VERSION ""

NS_ :

BS_:

BU_: DAS IRTS_FR STEER DAS TLM IRTS_FR STEER DAS TLM IRTS_FR DAS BMS_LV DAS IRTS_RR BMS_HV IRTS_FR DAS DAS DAS IRTS_RR STEER IRTS_FL DAS TLM DAS IRTS_RR TLM IRTS_FL DAS STEER DAS IRTS_RR STEER IRTS_FL DAS TLM DAS IRTS_RL STEER IRTS_FL DAS TELEMETRY DAS IRTS_RL DAS IMU DAS CONTROL DAS IRTS_RL TELEMETRY IMU DAS DAS IRTS_RL STEER DAS

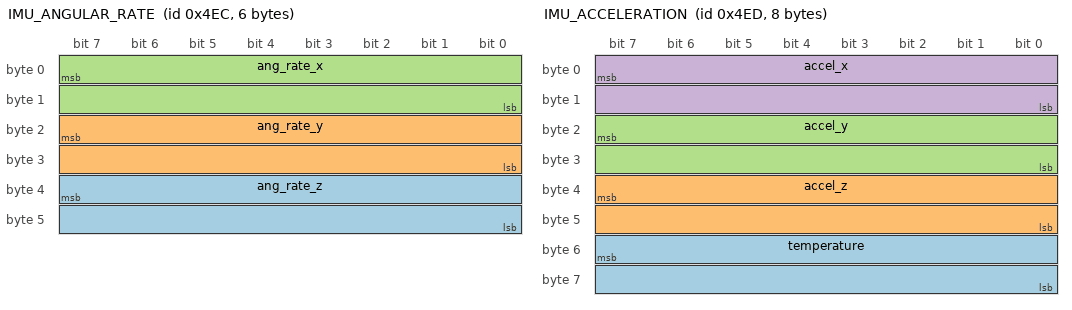
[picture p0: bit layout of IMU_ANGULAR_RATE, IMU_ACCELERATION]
BO_ 1260 IMU_ANGULAR_RATE: 6 Vector__XXX
 SG_ ang_rate_z : 39|16@0- (0.1,0) [0|245] "" Vector__XXX
 SG_ ang_rate_y : 23|16@0- (0.1,0) [0|245] "" Vector__XXX
 SG_ ang_rate_x : 7|16@0- (0.1,0) [0|245] "" Vector__XXX

BO_ 1261 IMU_ACCELERATION: 8 Vector__XXX
 SG_ temperature : 55|16@0- (1,-32768) [-32768|32767] "" Vector__XXX
 SG_ accel_z : 39|16@0- (0.01,0) [0|8] "" Vector__XXX
 SG_ accel_y : 23|16@0- (0.01,0) [0|8] "" Vector__XXX
 SG_ accel_x : 7|16@0- (0.01,0) [0|8] "" Vector__XXX

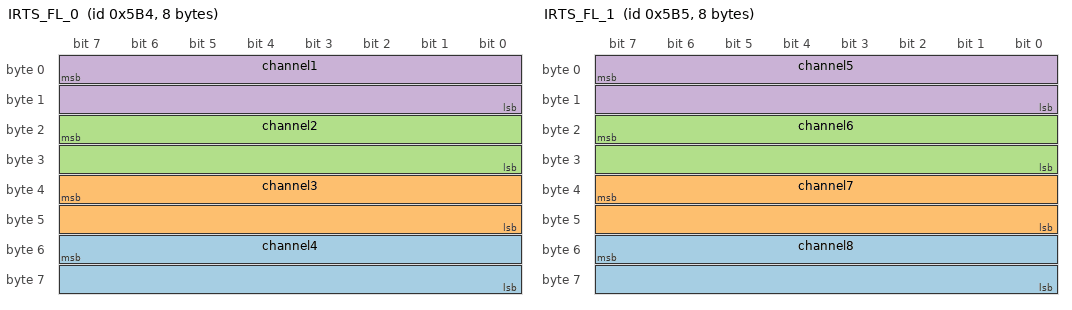
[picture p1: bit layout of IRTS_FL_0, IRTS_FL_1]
BO_ 1460 IRTS_FL_0: 8 Vector__XXX
 SG_ channel4 : 55|16@0+ (0.09775171065493646,-100) [-100|0] "" Vector__XXX
 SG_ channel3 : 39|16@0+ (0.09775171065493646,-100) [-100|0] "" Vector__XXX
 SG_ channel2 : 23|16@0+ (0.09775171065493646,-100) [-100|0] "" Vector__XXX
 SG_ channel1 : 7|16@0+ (0.09775171065493646,-100) [-100|0] "" Vector__XXX

BO_ 1461 IRTS_FL_1: 8 Vector__XXX
 SG_ channel8 : 55|16@0+ (0.09775171065493646,-100) [-100|0] "" Vector__XXX
 SG_ channel7 : 39|16@0+ (0.09775171065493646,-100) [-100|0] "" Vector__XXX
 SG_ channel6 : 23|16@0+ (0.09775171065493646,-100) [-100|0] "" Vector__XXX
 SG_ channel5 : 7|16@0+ (0.09775171065493646,-100) [-100|0] "" Vector__XXX

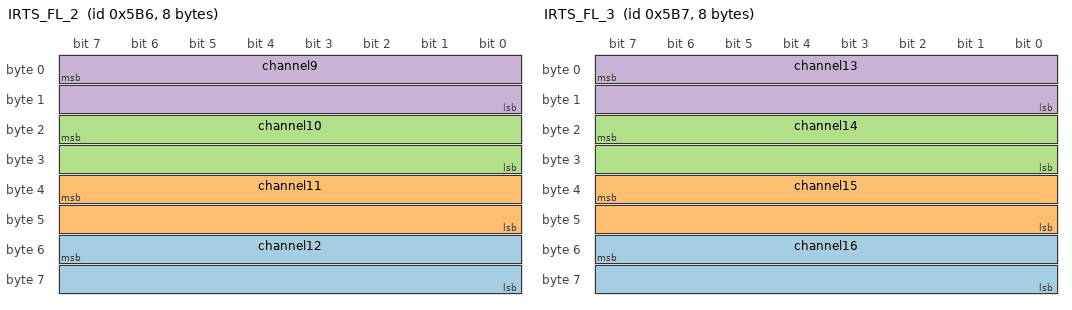
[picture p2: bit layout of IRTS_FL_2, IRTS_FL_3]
BO_ 1462 IRTS_FL_2: 8 Vector__XXX
 SG_ channel12 : 55|16@0+ (0.09775171065493646,-100) [-100|0] "" Vector__XXX
 SG_ channel11 : 39|16@0+ (0.09775171065493646,-100) [-100|0] "" Vector__XXX
 SG_ channel10 : 23|16@0+ (0.09775171065493646,-100) [-100|0] "" Vector__XXX
 SG_ channel9 : 7|16@0+ (0.09775171065493646,-100) [-100|0] "" Vector__XXX

BO_ 1463 IRTS_FL_3: 8 Vector__XXX
 SG_ channel16 : 55|16@0+ (0.09775171065493646,-100) [-100|0] "" Vector__XXX
 SG_ channel15 : 39|16@0+ (0.09775171065493646,-100) [-100|0] "" Vector__XXX
 SG_ channel14 : 23|16@0+ (0.09775171065493646,-100) [-100|0] "" Vector__XXX
 SG_ channel13 : 7|16@0+ (0.09775171065493646,-100) [-100|0] "" Vector__XXX

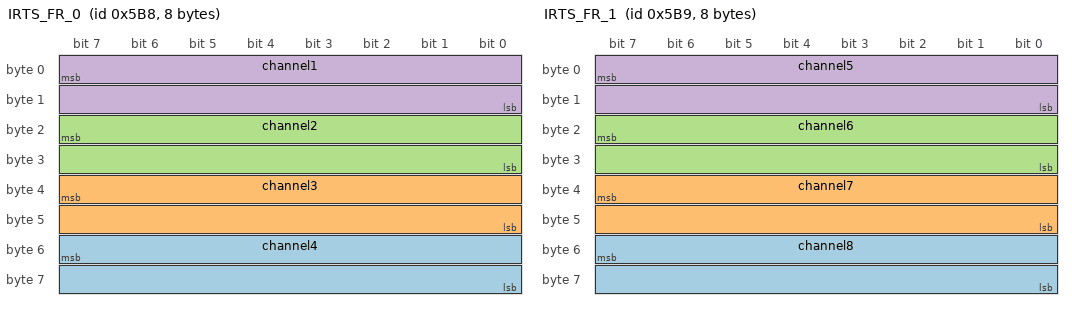
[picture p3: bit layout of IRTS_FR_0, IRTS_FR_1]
BO_ 1464 IRTS_FR_0: 8 Vector__XXX
 SG_ channel4 : 55|16@0+ (0.09775171065493646,-100) [-100|0] "" Vector__XXX
 SG_ channel3 : 39|16@0+ (0.09775171065493646,-100) [-100|0] "" Vector__XXX
 SG_ channel2 : 23|16@0+ (0.09775171065493646,-100) [-100|0] "" Vector__XXX
 SG_ channel1 : 7|16@0+ (0.09775171065493646,-100) [-100|0] "" Vector__XXX

BO_ 1465 IRTS_FR_1: 8 Vector__XXX
 SG_ channel8 : 55|16@0+ (0.09775171065493646,-100) [-100|0] "" Vector__XXX
 SG_ channel7 : 39|16@0+ (0.09775171065493646,-100) [-100|0] "" Vector__XXX
 SG_ channel6 : 23|16@0+ (0.09775171065493646,-100) [-100|0] "" Vector__XXX
 SG_ channel5 : 7|16@0+ (0.09775171065493646,-100) [-100|0] "" Vector__XXX

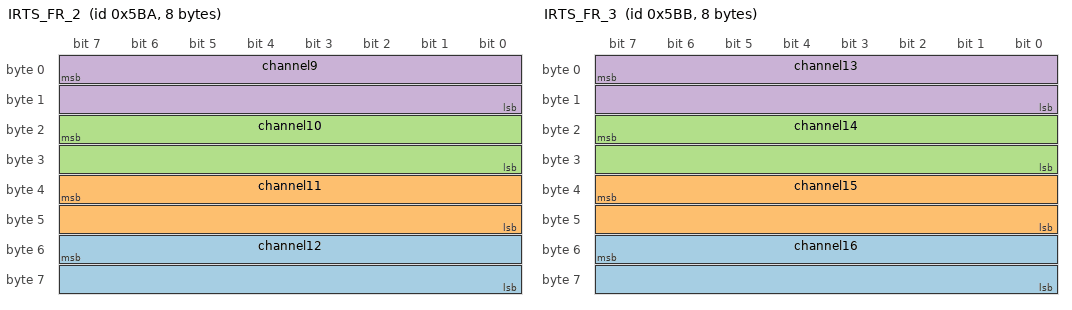
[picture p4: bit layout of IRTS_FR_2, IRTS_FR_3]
BO_ 1466 IRTS_FR_2: 8 Vector__XXX
 SG_ channel12 : 55|16@0+ (0.09775171065493646,-100) [-100|0] "" Vector__XXX
 SG_ channel11 : 39|16@0+ (0.09775171065493646,-100) [-100|0] "" Vector__XXX
 SG_ channel10 : 23|16@0+ (0.09775171065493646,-100) [-100|0] "" Vector__XXX
 SG_ channel9 : 7|16@0+ (0.09775171065493646,-100) [-100|0] "" Vector__XXX

BO_ 1467 IRTS_FR_3: 8 Vector__XXX
 SG_ channel16 : 55|16@0+ (0.09775171065493646,-100) [-100|0] "" Vector__XXX
 SG_ channel15 : 39|16@0+ (0.09775171065493646,-100) [-100|0] "" Vector__XXX
 SG_ channel14 : 23|16@0+ (0.09775171065493646,-100) [-100|0] "" Vector__XXX
 SG_ channel13 : 7|16@0+ (0.09775171065493646,-100) [-100|0] "" Vector__XXX

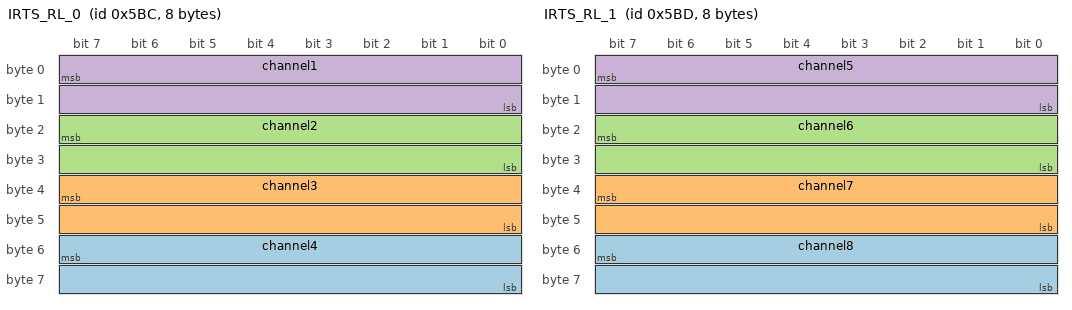
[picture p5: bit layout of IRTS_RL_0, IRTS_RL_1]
BO_ 1468 IRTS_RL_0: 8 Vector__XXX
 SG_ channel4 : 55|16@0+ (0.09775171065493646,-100) [-100|0] "" Vector__XXX
 SG_ channel3 : 39|16@0+ (0.09775171065493646,-100) [-100|0] "" Vector__XXX
 SG_ channel2 : 23|16@0+ (0.09775171065493646,-100) [-100|0] "" Vector__XXX
 SG_ channel1 : 7|16@0+ (0.09775171065493646,-100) [-100|0] "" Vector__XXX

BO_ 1469 IRTS_RL_1: 8 Vector__XXX
 SG_ channel8 : 55|16@0+ (0.09775171065493646,-100) [-100|0] "" Vector__XXX
 SG_ channel7 : 39|16@0+ (0.09775171065493646,-100) [-100|0] "" Vector__XXX
 SG_ channel6 : 23|16@0+ (0.09775171065493646,-100) [-100|0] "" Vector__XXX
 SG_ channel5 : 7|16@0+ (0.09775171065493646,-100) [-100|0] "" Vector__XXX

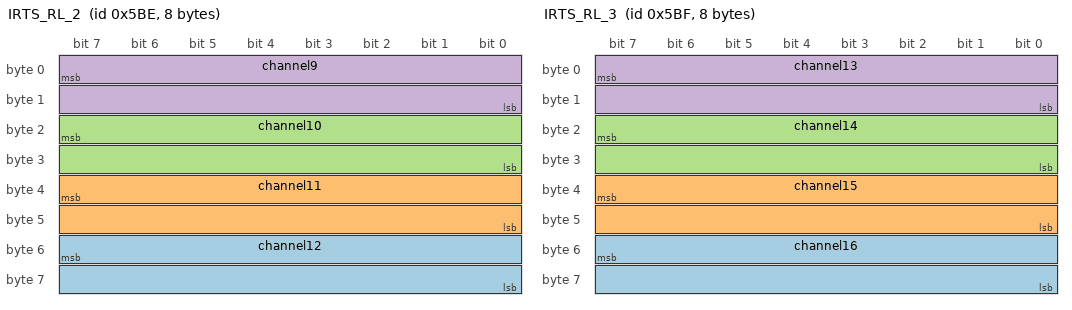
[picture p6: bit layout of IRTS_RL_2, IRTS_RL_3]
BO_ 1470 IRTS_RL_2: 8 Vector__XXX
 SG_ channel12 : 55|16@0+ (0.09775171065493646,-100) [-100|0] "" Vector__XXX
 SG_ channel11 : 39|16@0+ (0.09775171065493646,-100) [-100|0] "" Vector__XXX
 SG_ channel10 : 23|16@0+ (0.09775171065493646,-100) [-100|0] "" Vector__XXX
 SG_ channel9 : 7|16@0+ (0.09775171065493646,-100) [-100|0] "" Vector__XXX

BO_ 1471 IRTS_RL_3: 8 Vector__XXX
 SG_ channel16 : 55|16@0+ (0.09775171065493646,-100) [-100|0] "" Vector__XXX
 SG_ channel15 : 39|16@0+ (0.09775171065493646,-100) [-100|0] "" Vector__XXX
 SG_ channel14 : 23|16@0+ (0.09775171065493646,-100) [-100|0] "" Vector__XXX
 SG_ channel13 : 7|16@0+ (0.09775171065493646,-100) [-100|0] "" Vector__XXX

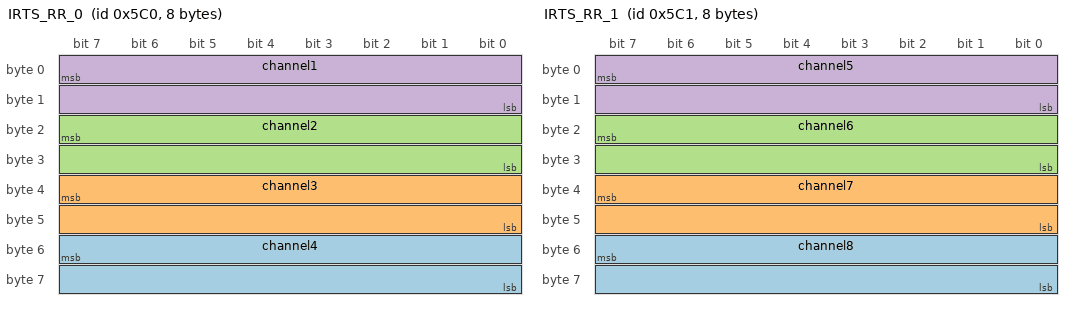
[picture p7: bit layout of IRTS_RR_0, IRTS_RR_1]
BO_ 1472 IRTS_RR_0: 8 Vector__XXX
 SG_ channel4 : 55|16@0+ (0.09775171065493646,-100) [-100|0] "" Vector__XXX
 SG_ channel3 : 39|16@0+ (0.09775171065493646,-100) [-100|0] "" Vector__XXX
 SG_ channel2 : 23|16@0+ (0.09775171065493646,-100) [-100|0] "" Vector__XXX
 SG_ channel1 : 7|16@0+ (0.09775171065493646,-100) [-100|0] "" Vector__XXX

BO_ 1473 IRTS_RR_1: 8 Vector__XXX
 SG_ channel8 : 55|16@0+ (0.09775171065493646,-100) [-100|0] "" Vector__XXX
 SG_ channel7 : 39|16@0+ (0.09775171065493646,-100) [-100|0] "" Vector__XXX
 SG_ channel6 : 23|16@0+ (0.09775171065493646,-100) [-100|0] "" Vector__XXX
 SG_ channel5 : 7|16@0+ (0.09775171065493646,-100) [-100|0] "" Vector__XXX

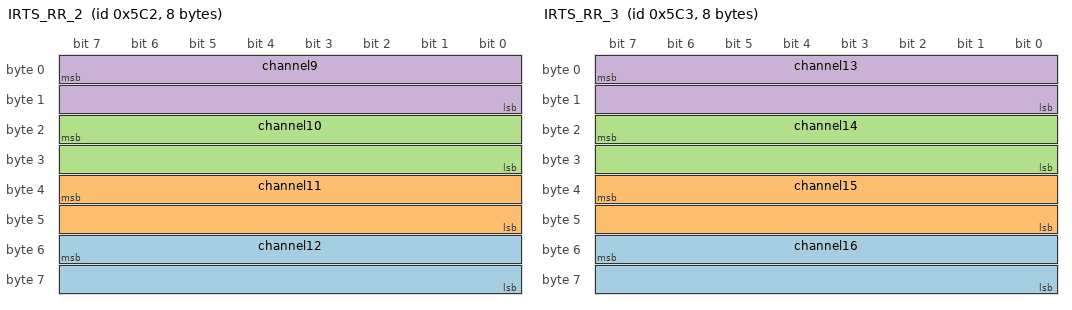
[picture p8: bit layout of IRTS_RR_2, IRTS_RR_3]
BO_ 1474 IRTS_RR_2: 8 Vector__XXX
 SG_ channel12 : 55|16@0+ (0.09775171065493646,-100) [-100|0] "" Vector__XXX
 SG_ channel11 : 39|16@0+ (0.09775171065493646,-100) [-100|0] "" Vector__XXX
 SG_ channel10 : 23|16@0+ (0.09775171065493646,-100) [-100|0] "" Vector__XXX
 SG_ channel9 : 7|16@0+ (0.09775171065493646,-100) [-100|0] "" Vector__XXX

BO_ 1475 IRTS_RR_3: 8 Vector__XXX
 SG_ channel16 : 55|16@0+ (0.09775171065493646,-100) [-100|0] "" Vector__XXX
 SG_ channel15 : 39|16@0+ (0.09775171065493646,-100) [-100|0] "" Vector__XXX
 SG_ channel14 : 23|16@0+ (0.09775171065493646,-100) [-100|0] "" Vector__XXX
 SG_ channel13 : 7|16@0+ (0.09775171065493646,-100) [-100|0] "" Vector__XXX

BO_ 1025 GPS_COORDS: 8 Vector__XXX
 SG_ longitude : 32|32@1+ (1,0) [0|4294967295] "" Vector__XXX
 SG_ latitude : 0|32@1+ (1,0) [0|4294967295] "" Vector__XXX

BO_ 1057 GPS_SPEED: 2 Vector__XXX
 SG_ speed : 0|16@1+ (1,0) [0|65535] "" Vector__XXX

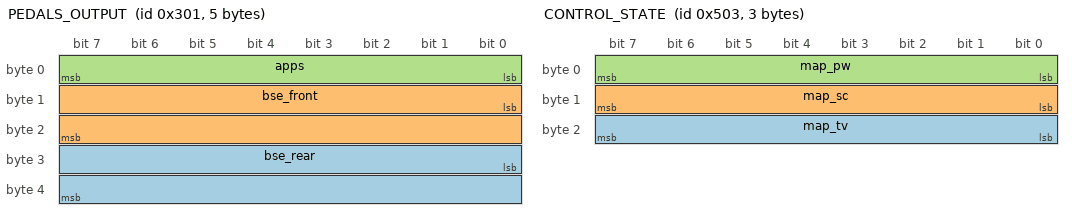
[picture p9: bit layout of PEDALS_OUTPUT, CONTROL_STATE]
BO_ 769 PEDALS_OUTPUT: 5 Vector__XXX
 SG_ bse_rear : 24|16@1+ (0.0015259021896696422,0) [0|100] "" Vector__XXX
 SG_ bse_front : 8|16@1+ (0.0015259021896696422,0) [0|100] "" Vector__XXX
 SG_ apps : 0|8@1+ (1,0) [0|255] "" Vector__XXX

BO_ 258 STEERING_ANGLE: 4 Vector__XXX
 SG_ angle : 0|32@1+ (1.676380634698174e-07,-360) [-360|360] "" Vector__XXX

BO_ 1283 CONTROL_STATE: 3 Vector__XXX
 SG_ map_tv : 16|8@1+ (0.06666666666666667,0) [0|1] "" Vector__XXX
 SG_ map_sc : 8|8@1+ (0.06666666666666667,0) [0|1] "" Vector__XXX
 SG_ map_pw : 0|8@1+ (0.1,-0.5) [-0.5|1] "" Vector__XXX

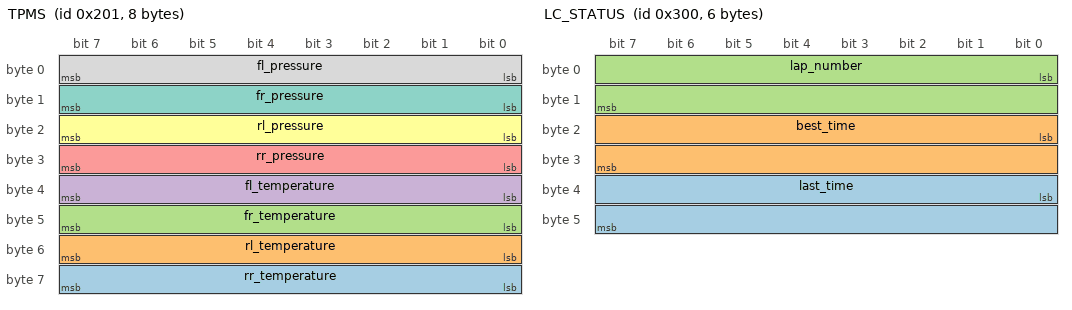
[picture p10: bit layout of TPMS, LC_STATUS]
BO_ 513 TPMS: 8 Vector__XXX
 SG_ rr_temperature : 56|8@1+ (1,0) [0|255] "" Vector__XXX
 SG_ rl_temperature : 48|8@1+ (1,0) [0|255] "" Vector__XXX
 SG_ fr_temperature : 40|8@1+ (1,0) [0|255] "" Vector__XXX
 SG_ fl_temperature : 32|8@1+ (1,0) [0|255] "" Vector__XXX
 SG_ rr_pressure : 24|8@1+ (0.0967741935483871,0) [0|3] "" Vector__XXX
 SG_ rl_pressure : 16|8@1+ (0.0967741935483871,0) [0|3] "" Vector__XXX
 SG_ fr_pressure : 8|8@1+ (0.0967741935483871,0) [0|3] "" Vector__XXX
 SG_ fl_pressure : 0|8@1+ (0.0967741935483871,0) [0|3] "" Vector__XXX

BO_ 1089 LAP_COUNT: 4 Vector__XXX
 SG_ lap_time : 16|16@1+ (0.015259021896696421,0) [0|1000] "" Vector__XXX
 SG_ lap_count : 0|16@1+ (1,0) [0|65535] "" Vector__XXX

BO_ 768 LC_STATUS: 6 Vector__XXX
 SG_ last_time : 32|16@1+ (0.015259021896696421,0) [0|1000] "" Vector__XXX
 SG_ best_time : 16|16@1+ (0.015259021896696421,0) [0|1000] "" Vector__XXX
 SG_ lap_number : 0|16@1+ (1,0) [0|65535] "" Vector__XXX

BO_ 260 TIMESTAMP: 8 Vector__XXX
 SG_ timestamp : 0|64@1+ (1,0) [0|18446744073709551615] "" Vector__XXX

CM_ BO_ 1260 "Inertial Measurement Unit [x,y,z]-axis angular rate value. 0.01dps per bit, Big-Endian, 16bit Total, signed";
CM_ BO_ 1261 "Inertial Measurement Unit [x,y,z]-axis acceleration value. 0.01g per bit, Big-Endian, 16bit Total, signed";
CM_ BO_ 1460 "Front Left wheel InfraRed Temperature Sensor data, channels 1 through 4. 0.1˚C per bit, -100˚C offset, Big-Endian, 16bit Total, unsigned.";
CM_ BO_ 1461 "Front Left wheel InfraRed Temperature Sensor data, channels 5 through 8. 0.1˚C per bit, -100˚C offset, Big-Endian, 16bit Total, unsigned.";
CM_ BO_ 1462 "Front Left wheel InfraRed Temperature Sensor data, channels 9 through 12. 0.1˚C per bit, -100˚C offset, Big-Endian, 16bit Total, unsigned.";
CM_ BO_ 1463 "Front Left wheel InfraRed Temperature Sensor data, channels 13 through 16. 0.1˚C per bit, -100˚C offset, Big-Endian, 16bit Total, unsigned.";
CM_ BO_ 1464 "Front Right wheel InfraRed Temperature Sensor data, channels 1 through 4. 0.1˚C per bit, -100˚C offset, Big-Endian, 16bit Total, unsigned.";
CM_ BO_ 1465 "Front Right wheel InfraRed Temperature Sensor data, channels 5 through 8. 0.1˚C per bit, -100˚C offset, Big-Endian, 16bit Total, unsigned.";
CM_ BO_ 1466 "Front Right wheel InfraRed Temperature Sensor data, channels 9 through 12. 0.1˚C per bit, -100˚C offset, Big-Endian, 16bit Total, unsigned.";
CM_ BO_ 1467 "Front Right wheel InfraRed Temperature Sensor data, channels 13 through 16. 0.1˚C per bit, -100˚C offset, Big-Endian, 16bit Total, unsigned.";
CM_ BO_ 1468 "Rear Left wheel InfraRed Temperature Sensor data, channels 1 through 4. 0.1˚C per bit, -100˚C offset, Big-Endian, 16bit Total, unsigned.";
CM_ BO_ 1469 "Rear Left wheel InfraRed Temperature Sensor data, channels 5 through 8. 0.1˚C per bit, -100˚C offset, Big-Endian, 16bit Total, unsigned.";
CM_ BO_ 1470 "Rear Left wheel InfraRed Temperature Sensor data, channels 9 through 12. 0.1˚C per bit, -100˚C offset, Big-Endian, 16bit Total, unsigned.";
CM_ BO_ 1471 "Rear Left wheel InfraRed Temperature Sensor data, channels 13 through 16. 0.1˚C per bit, -100˚C offset, Big-Endian, 16bit Total, unsigned.";
CM_ BO_ 1472 "Rear Right wheel InfraRed Temperature Sensor data, channels 1 through 4. 0.1˚C per bit, -100˚C offset, Big-Endian, 16bit Total, unsigned.";
CM_ BO_ 1473 "Rear Right wheel InfraRed Temperature Sensor data, channels 5 through 8. 0.1˚C per bit, -100˚C offset, Big-Endian, 16bit Total, unsigned.";
CM_ BO_ 1474 "Rear Right wheel InfraRed Temperature Sensor data, channels 9 through 12. 0.1˚C per bit, -100˚C offset, Big-Endian, 16bit Total, unsigned.";
CM_ BO_ 1475 "Rear Right wheel InfraRed Temperature Sensor data, channels 13 through 16. 0.1˚C per bit, -100˚C offset, Big-Endian, 16bit Total, unsigned.";
CM_ BO_ 1025 "Coordinates received from GPS";
CM_ BO_ 1057 "Speed received from GPS";
CM_ BO_ 769 "Pedal output, already calibrated";
CM_ BO_ 258 "Steering angle in degrees";
CM_ BO_ 1283 "Send status of traction control";
CM_ BO_ 513 "Tire Pressure Monitoring System, pressure and temperature of each tire";
CM_ BO_ 1089 "On new lap";
CM_ BO_ 768 "Session laps status";
CM_ BO_ 260 "every second unix encoded time and date used by logging devices to sync";
BA_DEF_ BO_  "GenMsgCycleTime" INT 0 65535;
BA_DEF_DEF_  "GenMsgCycleTime" 0;
BA_ "GenMsgCycleTime" BO_ 769 10;
BA_ "GenMsgCycleTime" BO_ 258 10;
BA_ "GenMsgCycleTime" BO_ 1283 100;
BA_ "GenMsgCycleTime" BO_ 260 500;
